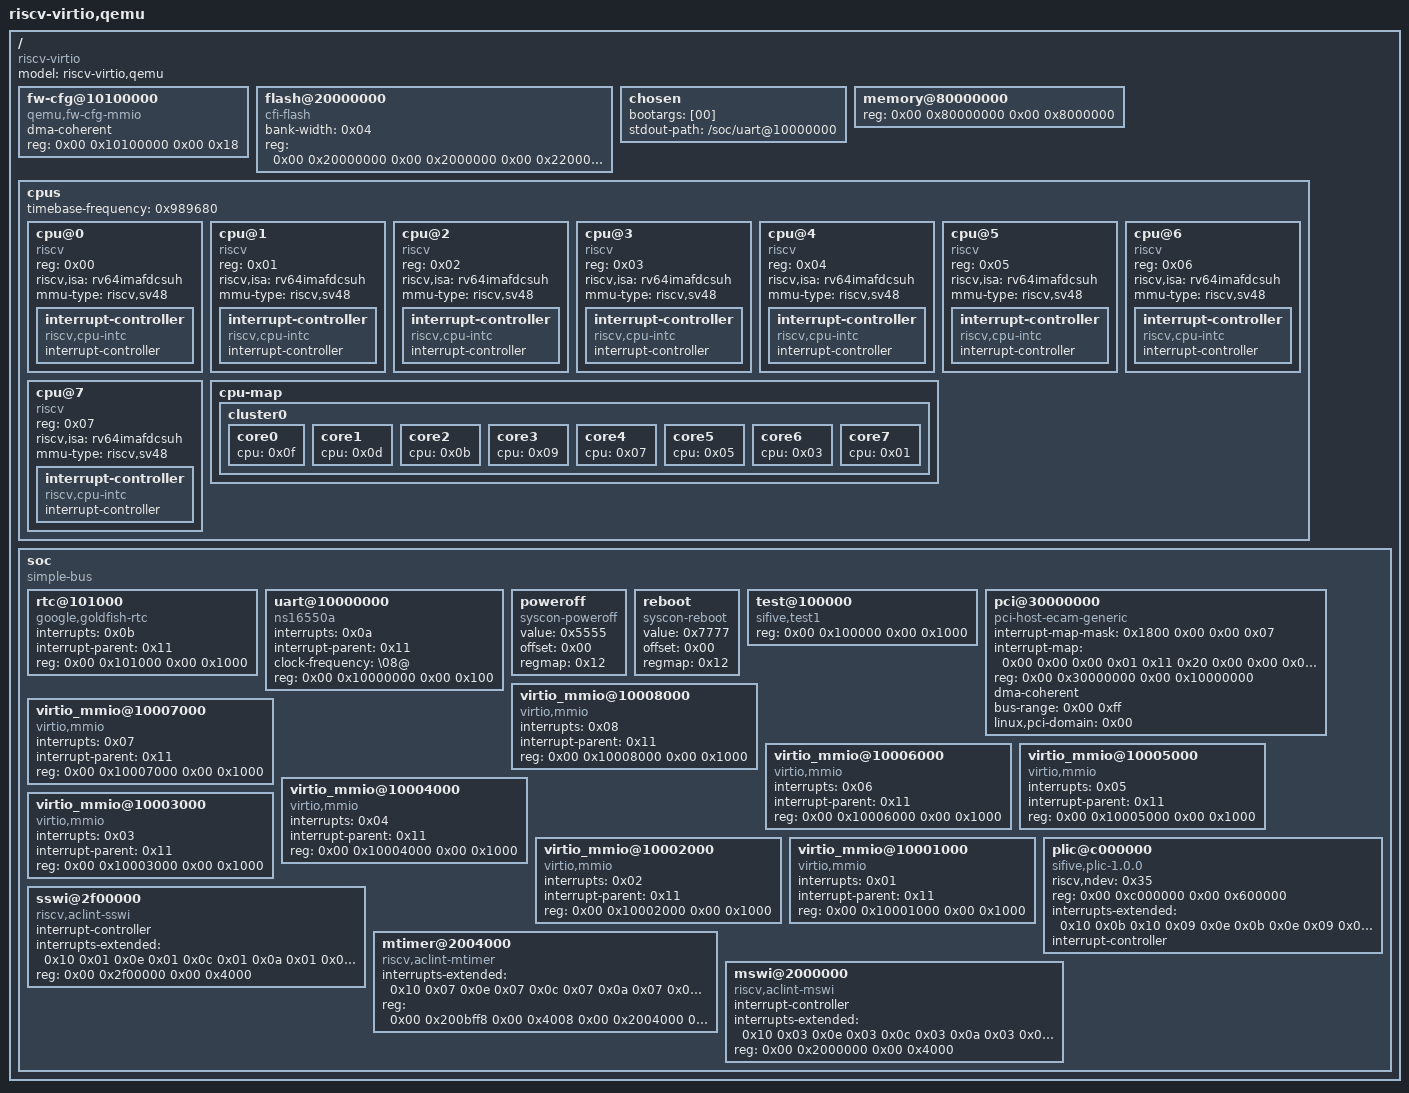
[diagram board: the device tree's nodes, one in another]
/dts-v1/;

/ {
	#address-cells = <0x02>;
	#size-cells = <0x02>;
	compatible = "riscv-virtio";
	model = "riscv-virtio,qemu";

	fw-cfg@10100000 {
		dma-coherent;
		reg = <0x00 0x10100000 0x00 0x18>;
		compatible = "qemu,fw-cfg-mmio";
	};

	flash@20000000 {
		bank-width = <0x04>;
		reg = <0x00 0x20000000 0x00 0x2000000 0x00 0x22000000 0x00 0x2000000>;
		compatible = "cfi-flash";
	};

	chosen {
		bootargs = [00];
		stdout-path = "/soc/uart@10000000";
	};

	memory@80000000 {
		device_type = "memory";
		reg = <0x00 0x80000000 0x00 0x8000000>;
	};

	cpus {
		#address-cells = <0x01>;
		#size-cells = <0x00>;
		timebase-frequency = <0x989680>;

		cpu@0 {
			phandle = <0x0f>;
			device_type = "cpu";
			reg = <0x00>;
			status = "okay";
			compatible = "riscv";
			riscv,isa = "rv64imafdcsuh";
			mmu-type = "riscv,sv48";

			interrupt-controller {
				#interrupt-cells = <0x01>;
				interrupt-controller;
				compatible = "riscv,cpu-intc";
				phandle = <0x10>;
			};
		};

		cpu@1 {
			phandle = <0x0d>;
			device_type = "cpu";
			reg = <0x01>;
			status = "okay";
			compatible = "riscv";
			riscv,isa = "rv64imafdcsuh";
			mmu-type = "riscv,sv48";

			interrupt-controller {
				#interrupt-cells = <0x01>;
				interrupt-controller;
				compatible = "riscv,cpu-intc";
				phandle = <0x0e>;
			};
		};

		cpu@2 {
			phandle = <0x0b>;
			device_type = "cpu";
			reg = <0x02>;
			status = "okay";
			compatible = "riscv";
			riscv,isa = "rv64imafdcsuh";
			mmu-type = "riscv,sv48";

			interrupt-controller {
				#interrupt-cells = <0x01>;
				interrupt-controller;
				compatible = "riscv,cpu-intc";
				phandle = <0x0c>;
			};
		};

		cpu@3 {
			phandle = <0x09>;
			device_type = "cpu";
			reg = <0x03>;
			status = "okay";
			compatible = "riscv";
			riscv,isa = "rv64imafdcsuh";
			mmu-type = "riscv,sv48";

			interrupt-controller {
				#interrupt-cells = <0x01>;
				interrupt-controller;
				compatible = "riscv,cpu-intc";
				phandle = <0x0a>;
			};
		};

		cpu@4 {
			phandle = <0x07>;
			device_type = "cpu";
			reg = <0x04>;
			status = "okay";
			compatible = "riscv";
			riscv,isa = "rv64imafdcsuh";
			mmu-type = "riscv,sv48";

			interrupt-controller {
				#interrupt-cells = <0x01>;
				interrupt-controller;
				compatible = "riscv,cpu-intc";
				phandle = <0x08>;
			};
		};

		cpu@5 {
			phandle = <0x05>;
			device_type = "cpu";
			reg = <0x05>;
			status = "okay";
			compatible = "riscv";
			riscv,isa = "rv64imafdcsuh";
			mmu-type = "riscv,sv48";

			interrupt-controller {
				#interrupt-cells = <0x01>;
				interrupt-controller;
				compatible = "riscv,cpu-intc";
				phandle = <0x06>;
			};
		};

		cpu@6 {
			phandle = <0x03>;
			device_type = "cpu";
			reg = <0x06>;
			status = "okay";
			compatible = "riscv";
			riscv,isa = "rv64imafdcsuh";
			mmu-type = "riscv,sv48";

			interrupt-controller {
				#interrupt-cells = <0x01>;
				interrupt-controller;
				compatible = "riscv,cpu-intc";
				phandle = <0x04>;
			};
		};

		cpu@7 {
			phandle = <0x01>;
			device_type = "cpu";
			reg = <0x07>;
			status = "okay";
			compatible = "riscv";
			riscv,isa = "rv64imafdcsuh";
			mmu-type = "riscv,sv48";

			interrupt-controller {
				#interrupt-cells = <0x01>;
				interrupt-controller;
				compatible = "riscv,cpu-intc";
				phandle = <0x02>;
			};
		};

		cpu-map {

			cluster0 {

				core0 {
					cpu = <0x0f>;
				};

				core1 {
					cpu = <0x0d>;
				};

				core2 {
					cpu = <0x0b>;
				};

				core3 {
					cpu = <0x09>;
				};

				core4 {
					cpu = <0x07>;
				};

				core5 {
					cpu = <0x05>;
				};

				core6 {
					cpu = <0x03>;
				};

				core7 {
					cpu = <0x01>;
				};
			};
		};
	};

	soc {
		#address-cells = <0x02>;
		#size-cells = <0x02>;
		compatible = "simple-bus";
		ranges;

		rtc@101000 {
			interrupts = <0x0b>;
			interrupt-parent = <0x11>;
			reg = <0x00 0x101000 0x00 0x1000>;
			compatible = "google,goldfish-rtc";
		};

		uart@10000000 {
			interrupts = <0x0a>;
			interrupt-parent = <0x11>;
			clock-frequency = "\08@";
			reg = <0x00 0x10000000 0x00 0x100>;
			compatible = "ns16550a";
		};

		poweroff {
			value = <0x5555>;
			offset = <0x00>;
			regmap = <0x12>;
			compatible = "syscon-poweroff";
		};

		reboot {
			value = <0x7777>;
			offset = <0x00>;
			regmap = <0x12>;
			compatible = "syscon-reboot";
		};

		test@100000 {
			phandle = <0x12>;
			reg = <0x00 0x100000 0x00 0x1000>;
			compatible = "sifive,test1\0sifive,test0\0syscon";
		};

		pci@30000000 {
			interrupt-map-mask = <0x1800 0x00 0x00 0x07>;
			interrupt-map = <0x00 0x00 0x00 0x01 0x11 0x20 0x00 0x00 0x00 0x02 0x11 0x21 0x00 0x00 0x00 0x03 0x11 0x22 0x00 0x00 0x00 0x04 0x11 0x23 0x800 0x00 0x00 0x01 0x11 0x21 0x800 0x00 0x00 0x02 0x11 0x22 0x800 0x00 0x00 0x03 0x11 0x23 0x800 0x00 0x00 0x04 0x11 0x20 0x1000 0x00 0x00 0x01 0x11 0x22 0x1000 0x00 0x00 0x02 0x11 0x23 0x1000 0x00 0x00 0x03 0x11 0x20 0x1000 0x00 0x00 0x04 0x11 0x21 0x1800 0x00 0x00 0x01 0x11 0x23 0x1800 0x00 0x00 0x02 0x11 0x20 0x1800 0x00 0x00 0x03 0x11 0x21 0x1800 0x00 0x00 0x04 0x11 0x22>;
			ranges = <0x1000000 0x00 0x00 0x00 0x3000000 0x00 0x10000 0x2000000 0x00 0x40000000 0x00 0x40000000 0x00 0x40000000 0x3000000 0x04 0x00 0x04 0x00 0x04 0x00>;
			reg = <0x00 0x30000000 0x00 0x10000000>;
			dma-coherent;
			bus-range = <0x00 0xff>;
			linux,pci-domain = <0x00>;
			device_type = "pci";
			compatible = "pci-host-ecam-generic";
			#size-cells = <0x02>;
			#interrupt-cells = <0x01>;
			#address-cells = <0x03>;
		};

		virtio_mmio@10008000 {
			interrupts = <0x08>;
			interrupt-parent = <0x11>;
			reg = <0x00 0x10008000 0x00 0x1000>;
			compatible = "virtio,mmio";
		};

		virtio_mmio@10007000 {
			interrupts = <0x07>;
			interrupt-parent = <0x11>;
			reg = <0x00 0x10007000 0x00 0x1000>;
			compatible = "virtio,mmio";
		};

		virtio_mmio@10006000 {
			interrupts = <0x06>;
			interrupt-parent = <0x11>;
			reg = <0x00 0x10006000 0x00 0x1000>;
			compatible = "virtio,mmio";
		};

		virtio_mmio@10005000 {
			interrupts = <0x05>;
			interrupt-parent = <0x11>;
			reg = <0x00 0x10005000 0x00 0x1000>;
			compatible = "virtio,mmio";
		};

		virtio_mmio@10004000 {
			interrupts = <0x04>;
			interrupt-parent = <0x11>;
			reg = <0x00 0x10004000 0x00 0x1000>;
			compatible = "virtio,mmio";
		};

		virtio_mmio@10003000 {
			interrupts = <0x03>;
			interrupt-parent = <0x11>;
			reg = <0x00 0x10003000 0x00 0x1000>;
			compatible = "virtio,mmio";
		};

		virtio_mmio@10002000 {
			interrupts = <0x02>;
			interrupt-parent = <0x11>;
			reg = <0x00 0x10002000 0x00 0x1000>;
			compatible = "virtio,mmio";
		};

		virtio_mmio@10001000 {
			interrupts = <0x01>;
			interrupt-parent = <0x11>;
			reg = <0x00 0x10001000 0x00 0x1000>;
			compatible = "virtio,mmio";
		};

		plic@c000000 {
			phandle = <0x11>;
			riscv,ndev = <0x35>;
			reg = <0x00 0xc000000 0x00 0x600000>;
			interrupts-extended = <0x10 0x0b 0x10 0x09 0x0e 0x0b 0x0e 0x09 0x0c 0x0b 0x0c 0x09 0x0a 0x0b 0x0a 0x09 0x08 0x0b 0x08 0x09 0x06 0x0b 0x06 0x09 0x04 0x0b 0x04 0x09 0x02 0x0b 0x02 0x09>;
			interrupt-controller;
			compatible = "sifive,plic-1.0.0\0riscv,plic0";
			#interrupt-cells = <0x01>;
		};

		sswi@2f00000 {
			#interrupt-cells = <0x00>;
			interrupt-controller;
			interrupts-extended = <0x10 0x01 0x0e 0x01 0x0c 0x01 0x0a 0x01 0x08 0x01 0x06 0x01 0x04 0x01 0x02 0x01>;
			reg = <0x00 0x2f00000 0x00 0x4000>;
			compatible = "riscv,aclint-sswi";
		};

		mtimer@2004000 {
			interrupts-extended = <0x10 0x07 0x0e 0x07 0x0c 0x07 0x0a 0x07 0x08 0x07 0x06 0x07 0x04 0x07 0x02 0x07>;
			reg = <0x00 0x200bff8 0x00 0x4008 0x00 0x2004000 0x00 0x7ff8>;
			compatible = "riscv,aclint-mtimer";
		};

		mswi@2000000 {
			#interrupt-cells = <0x00>;
			interrupt-controller;
			interrupts-extended = <0x10 0x03 0x0e 0x03 0x0c 0x03 0x0a 0x03 0x08 0x03 0x06 0x03 0x04 0x03 0x02 0x03>;
			reg = <0x00 0x2000000 0x00 0x4000>;
			compatible = "riscv,aclint-mswi";
		};
	};
};
